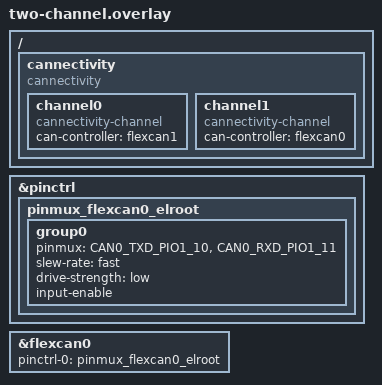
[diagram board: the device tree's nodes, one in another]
/* MCXN236 has two FlexCAN peripherals. Channel 0 uses the FRDM board's
 * existing FlexCAN1 routing. Channel 1 enables FlexCAN0 on PIO1_10/11;
 * no second transceiver is qualified on this board. */
&pinctrl {
	pinmux_flexcan0_elroot: pinmux_flexcan0_elroot {
		group0 {
			pinmux = <CAN0_TXD_PIO1_10>,
				 <CAN0_RXD_PIO1_11>;
			slew-rate = "fast";
			drive-strength = "low";
			input-enable;
		};
	};
};

&flexcan0 {
	status = "okay";
	pinctrl-0 = <&pinmux_flexcan0_elroot>;
	pinctrl-names = "default";
};

/ {
	cannectivity: cannectivity {
		compatible = "cannectivity";

		channel0 {
			compatible = "cannectivity-channel";
			can-controller = <&flexcan1>;
		};

		channel1 {
			compatible = "cannectivity-channel";
			can-controller = <&flexcan0>;
		};
	};
};
